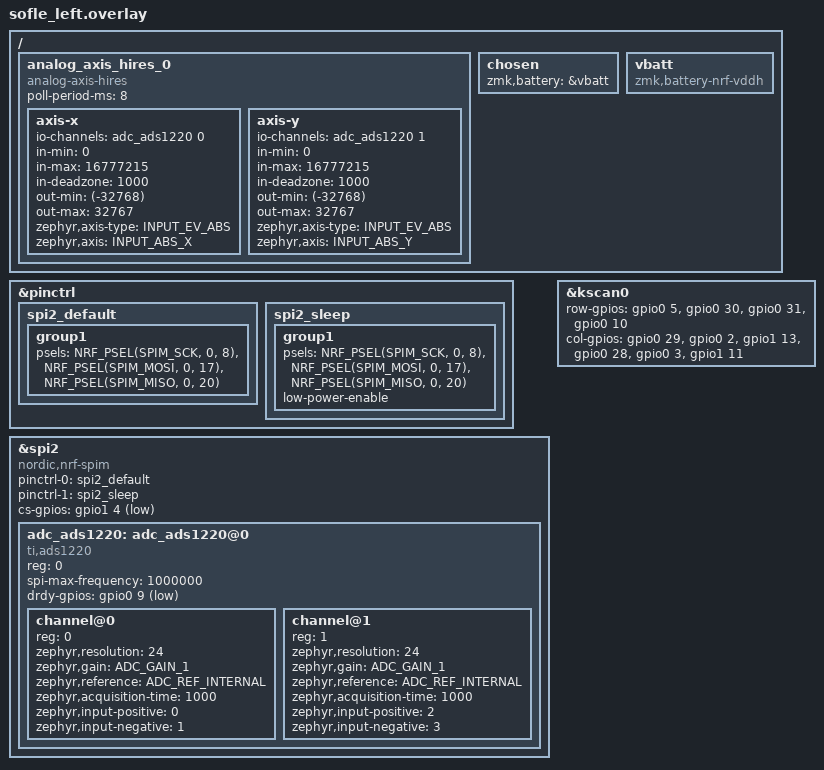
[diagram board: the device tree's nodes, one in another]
#include "sofle.dtsi"
#include <dt-bindings/spi/spi.h>
#include <zephyr/dt-bindings/input/input-event-codes.h>

&pinctrl {
    spi2_default: spi2_default { group1 { psels = <NRF_PSEL(SPIM_SCK, 0, 8)>, <NRF_PSEL(SPIM_MOSI, 0, 17)>, <NRF_PSEL(SPIM_MISO, 0, 20)>; }; };
    spi2_sleep: spi2_sleep { group1 { psels = <NRF_PSEL(SPIM_SCK, 0, 8)>, <NRF_PSEL(SPIM_MOSI, 0, 17)>, <NRF_PSEL(SPIM_MISO, 0, 20)>; low-power-enable; }; };
};

&spi2 {
    compatible = "nordic,nrf-spim";
    status = "okay";
    pinctrl-0 = <&spi2_default>;
    pinctrl-1 = <&spi2_sleep>;
    pinctrl-names = "default", "sleep";
    cs-gpios = <&gpio1 4 (GPIO_ACTIVE_LOW | GPIO_PULL_UP)>;
    adc_ads1220: adc_ads1220@0 {
        compatible = "ti,ads1220";
        status = "okay";
        reg = <0>;
        spi-max-frequency = <1000000>;
        #io-channel-cells = <1>;
        #address-cells = <1>;
        #size-cells = <0>;
        drdy-gpios = <&gpio0 9 (GPIO_ACTIVE_LOW | GPIO_PULL_UP)>;
        channel@0 { reg = <0>; zephyr,resolution = <24>; zephyr,gain = "ADC_GAIN_1"; zephyr,reference = "ADC_REF_INTERNAL"; zephyr,acquisition-time = <1000>; zephyr,input-positive = <0>; zephyr,input-negative = <1>; };
        channel@1 { reg = <1>; zephyr,resolution = <24>; zephyr,gain = "ADC_GAIN_1"; zephyr,reference = "ADC_REF_INTERNAL"; zephyr,acquisition-time = <1000>; zephyr,input-positive = <2>; zephyr,input-negative = <3>; };
    };
};

/ { analog_axis_hires_0: analog_axis_hires_0 { compatible = "analog-axis-hires"; status = "okay"; poll-period-ms = <8>;
    axis-x { io-channels = <&adc_ads1220 0>; in-min = <0>; in-max = <16777215>; in-deadzone = <1000>; out-min = <(-32768)>; out-max = <32767>; zephyr,axis-type = <INPUT_EV_ABS>; zephyr,axis = <INPUT_ABS_X>; };
    axis-y { io-channels = <&adc_ads1220 1>; in-min = <0>; in-max = <16777215>; in-deadzone = <1000>; out-min = <(-32768)>; out-max = <32767>; zephyr,axis-type = <INPUT_EV_ABS>; zephyr,axis = <INPUT_ABS_Y>; };
}; };

&kscan0 {
    row-gpios = <&gpio0 5 (GPIO_ACTIVE_HIGH | GPIO_PULL_DOWN)>, <&gpio0 30 (GPIO_ACTIVE_HIGH | GPIO_PULL_DOWN)>, <&gpio0 31 (GPIO_ACTIVE_HIGH | GPIO_PULL_DOWN)>, <&gpio0 10 (GPIO_ACTIVE_HIGH | GPIO_PULL_DOWN)>;
    col-gpios = <&gpio0 29 GPIO_ACTIVE_HIGH>, <&gpio0 2 GPIO_ACTIVE_HIGH>, <&gpio1 13 GPIO_ACTIVE_HIGH>, <&gpio0 28 GPIO_ACTIVE_HIGH>, <&gpio0 3 GPIO_ACTIVE_HIGH>, <&gpio1 11 GPIO_ACTIVE_HIGH>;
};
/ { chosen { zmk,battery = &vbatt; }; vbatt: vbatt { compatible = "zmk,battery-nrf-vddh"; }; };
